AUTOSAR XML (schema 00046)
package /Runnable_behavior
  sender receiver interface SR_IF_input
    data val1: type=uint16
    data val2: type=uint16
  sender receiver interface SR_IF_output
    data SumResult: type=uint32
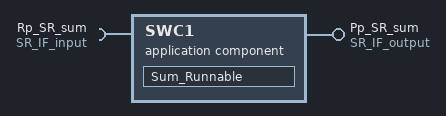
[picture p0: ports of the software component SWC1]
  application sw component type SWC1
    provide port Pp_SR_sum: provided-interface=SR_IF_output
    require port Rp_SR_sum: required-interface=SR_IF_input
    behavior SWC1_Behavior
      runnable Sum_Runnable: symbol=Set_CMD
        data-read-access:
          access Data_val1: accessed-variable=Rp_SR_sum.val1
          access Data_val1: accessed-variable=Rp_SR_sum.val2
        data-write-access:
          access Data_SumResult: accessed-variable=Pp_SR_sum.SumResult
